# netx90_app register map
File version: 1.0
CPU: CM4 r0p1, little endian, MPU, FPU, 4 interrupt priority bits, 78 interrupts
Registers are 32-bit, read-write, reset 0x0 unless marked. A register's access mark holds for its fields unless they carry their own. Offsets are from the block's base; [hi:lo] are bit positions; {n}, {i} and the like mark numbered series.

## madc
Base 0xFF4017E0
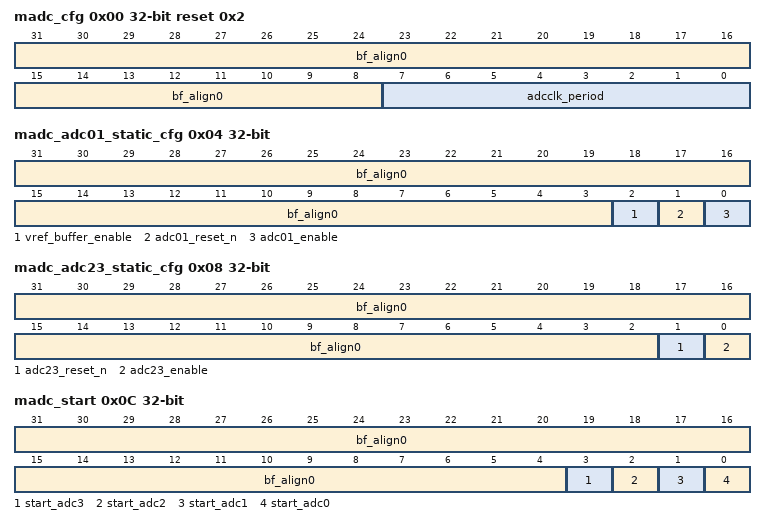
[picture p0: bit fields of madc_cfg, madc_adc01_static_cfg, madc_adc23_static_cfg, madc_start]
0x00 madc_cfg reset 0x2 (reset mask 0xFF) — Config bits for the MADC common module.
  [31:8] bf_align0 — bitField alignment value for aeabi compatibility
  [7:0] adcclk_period — Max value of global ADC synchronization counter: ADCs running at same adcclk might interfere. Therefore the ADCs should be able to run in different clk-phases. Adcclk generation will be done within the ADC sequencers. This value is used to configure a global counter for clock phase reference. It's value should be the same or an natural numbered multiple of the value configured in ADC sequencers.
0x04 madc_adc01_static_cfg (reset mask 0x7) — Static configuration signals (D2A) to the MAZ IP containing the analog modules ADC0 to ADC3.
  [31:3] bf_align0 — bitField alignment value for aeabi compatibility
  [2] vref_buffer_enable — Output Enable for internal Vref buffer Three modes are supported for generation of ADC Reference voltage (vref): { | 1. Use VDD3 (3,3V supply of analog core) as reference: This mode might be inaccurate due to jitter on VDD3. To enable this mode set static_cfg-vref=1 inside the related MADC_SEQ module. The vref_buffer_enable need not be set, if all ADCs use VDD3. 2. Use internal 2.6V reference: This mode requires an external capacitor at pin ADC_VREF, which will be driven to 2.6V from internal vref_buffer. To enable this mode set this bit to 1 and static_cfg-vref=0 inside the related MADC_SEQ module. 3. Use external reference: Use any external reference voltage (<3.3V) at pin ADC_VREF. To enable this mode set this bit to 0 and static_cfg-vref=0 inside the related MADC_SEQ module.}
  [1] adc01_reset_n — Low active reset of ADC0 and ADC1 and their state machines: 1: Soft-Reset is inactive. 0: Soft-Reset is active. A reset can be applied at any time during a currently running conversion cycle. There are no constraints on reset length.
  [0] adc01_enable — Power-down mode of ADC0 and ADC1: 1: Enable ADC (Power up) 0: Disable ADC (Power-down)
0x08 madc_adc23_static_cfg (reset mask 0x3) — Static configuration signals (D2A) to the MAZ IP containing the analog modules ADC0 to ADC3.
  [31:2] bf_align0 — bitField alignment value for aeabi compatibility
  [1] adc23_reset_n — Low active reset of ADC2 and ADC3 and their state machines: 1: Soft-Reset is inactive. 0: Soft-Reset is active. A reset can be applied at any time during a currently running conversion cycle. There are no constraints on reset length.
  [0] adc23_enable — Power-down mode of ADC2 and ADC3: 1: Enable ADC (Power up) 0: Disable ADC (Power-down)
0x0C madc_start (reset mask 0xF) — ADC start register: This register allows to start all ADCs in parallel. All further configuration is done within the ADC sequencers. Also ADCs can be started from their sequencers address range. This register is writable but can also be changed by hardware (reset).
  [31:4] bf_align0 — bitField alignment value for aeabi compatibility
  [3] start_adc3
  [2] start_adc2
  [1] start_adc1
  [0] start_adc0 — Start ADC0: Setting this bit to 1 starts ADC control state machine for ADC0. It will reset automatically after sampling phase. If it is reset, it can be set for next conversion. If start_adc0 and start_adc1 are set, the next conversion will be started after both ADCs are finished. Otherwise the next conversion will start directly after current conversion of ADC0 is finished.
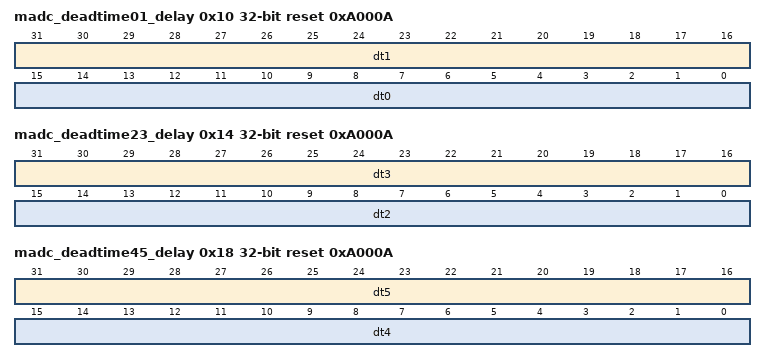
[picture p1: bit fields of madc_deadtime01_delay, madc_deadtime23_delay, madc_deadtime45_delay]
0x10 madc_deadtime01_delay reset 0xA000A — Dead time delay: Delay in steps of system clock (10ns) between Dead Time EVenT from PWM module and trigger. In case of 2nd DTEVT within delay time, the second DTEVT will be lost.
  [31:16] dt1 — delay for DTEVT[1]
  [15:0] dt0 — delay for DTEVT[0]
0x14 madc_deadtime23_delay reset 0xA000A — Dead time delay: Delay in steps of system clock (10ns) between Dead Time Event from PWM module and trigger. In case of 2nd Dead Time Event within delay time, the second DTEVT will be lost.
  [31:16] dt3 — delay for DTEVT[3]
  [15:0] dt2 — delay for DTEVT[2]
0x18 madc_deadtime45_delay reset 0xA000A — Dead time delay: Delay in steps of system clock (10ns) between Dead Time Event from PWM module and trigger. In case of 2nd Dead Time Event within delay time, the second DTEVT will be lost.
  [31:16] dt5 — delay for DTEVT[5]
  [15:0] dt4 — delay for DTEVT[4]
